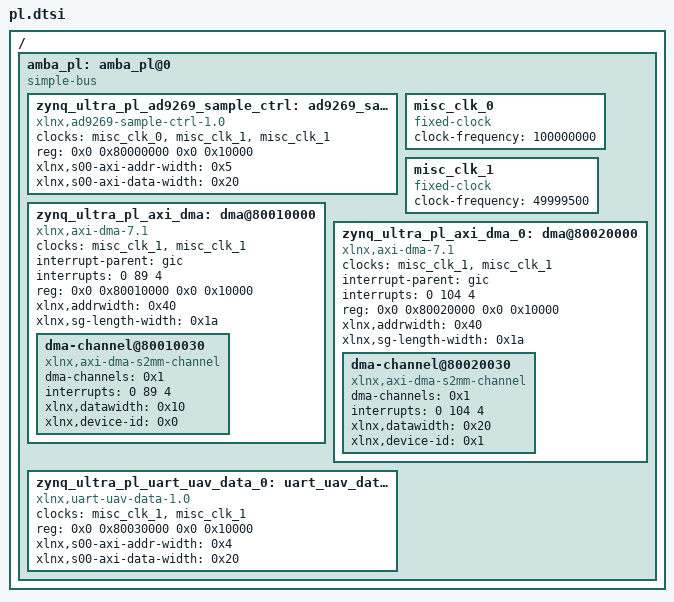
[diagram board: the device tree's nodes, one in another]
/*
 * CAUTION: This file is automatically generated by Xilinx.
 * Version:  
 * Today is: Sat Apr  5 15:54:22 2025
 */


/ {
	amba_pl: amba_pl@0 {
		#address-cells = <2>;
		#size-cells = <2>;
		compatible = "simple-bus";
		ranges ;
		zynq_ultra_pl_ad9269_sample_ctrl: ad9269_sample_ctrl@80000000 {
			clock-names = "adc_clk", "m00_axis_aclk", "s00_axi_aclk";
			clocks = <&misc_clk_0>, <&misc_clk_1>, <&misc_clk_1>;
			compatible = "xlnx,ad9269-sample-ctrl-1.0";
			reg = <0x0 0x80000000 0x0 0x10000>;
			xlnx,s00-axi-addr-width = <0x5>;
			xlnx,s00-axi-data-width = <0x20>;
		};
		misc_clk_0: misc_clk_0 {
			#clock-cells = <0>;
			clock-frequency = <100000000>;
			compatible = "fixed-clock";
		};
		misc_clk_1: misc_clk_1 {
			#clock-cells = <0>;
			clock-frequency = <49999500>;
			compatible = "fixed-clock";
		};
		zynq_ultra_pl_axi_dma: dma@80010000 {
			#dma-cells = <1>;
			clock-names = "s_axi_lite_aclk", "m_axi_s2mm_aclk";
			clocks = <&misc_clk_1>, <&misc_clk_1>;
			compatible = "xlnx,axi-dma-7.1", "xlnx,axi-dma-1.00.a";
			interrupt-names = "s2mm_introut";
			interrupt-parent = <&gic>;
			interrupts = <0 89 4>;
			reg = <0x0 0x80010000 0x0 0x10000>;
			xlnx,addrwidth = <0x40>;
			xlnx,sg-length-width = <0x1a>;
			dma-channel@80010030 {
				compatible = "xlnx,axi-dma-s2mm-channel";
				dma-channels = <0x1>;
				interrupts = <0 89 4>;
				xlnx,datawidth = <0x10>;
				xlnx,device-id = <0x0>;
			};
		};
		zynq_ultra_pl_axi_dma_0: dma@80020000 {
			#dma-cells = <1>;
			clock-names = "s_axi_lite_aclk", "m_axi_s2mm_aclk";
			clocks = <&misc_clk_1>, <&misc_clk_1>;
			compatible = "xlnx,axi-dma-7.1", "xlnx,axi-dma-1.00.a";
			interrupt-names = "s2mm_introut";
			interrupt-parent = <&gic>;
			interrupts = <0 104 4>;
			reg = <0x0 0x80020000 0x0 0x10000>;
			xlnx,addrwidth = <0x40>;
			xlnx,sg-length-width = <0x1a>;
			dma-channel@80020030 {
				compatible = "xlnx,axi-dma-s2mm-channel";
				dma-channels = <0x1>;
				interrupts = <0 104 4>;
				xlnx,datawidth = <0x20>;
				xlnx,device-id = <0x1>;
			};
		};
		zynq_ultra_pl_uart_uav_data_0: uart_uav_data@80030000 {
			clock-names = "s00_axi_aclk", "m00_axis_aclk";
			clocks = <&misc_clk_1>, <&misc_clk_1>;
			compatible = "xlnx,uart-uav-data-1.0";
			reg = <0x0 0x80030000 0x0 0x10000>;
			xlnx,s00-axi-addr-width = <0x4>;
			xlnx,s00-axi-data-width = <0x20>;
		};
	};
};
